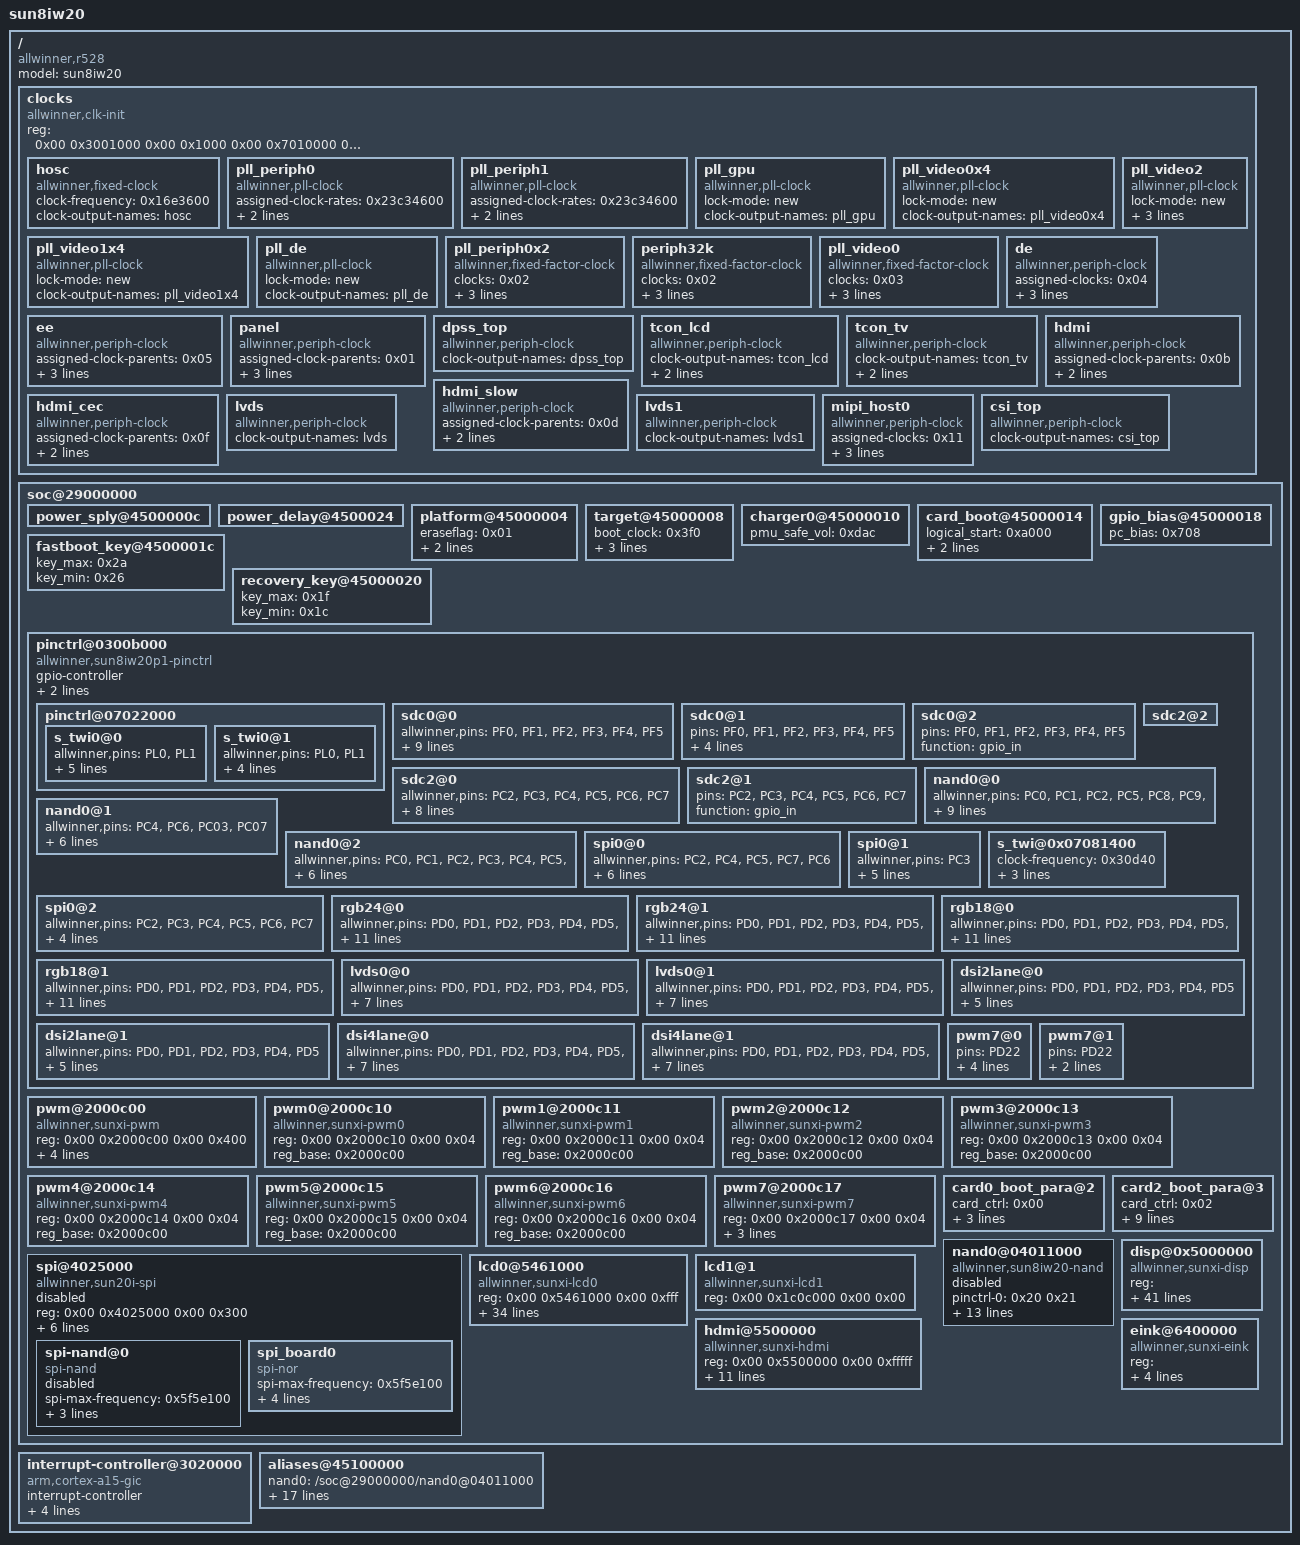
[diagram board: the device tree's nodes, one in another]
/dts-v1/;

/ {
	model = "sun8iw20";
	compatible = "allwinner,r528", "arm,sun8iw20p1";
	#address-cells = <0x02>;
	#size-cells = <0x02>;

	clocks {
		compatible = "allwinner,clk-init";
		device_type = "clocks";
		#address-cells = <0x02>;
		#size-cells = <0x02>;
		ranges;
		reg = <0x00 0x3001000 0x00 0x1000 0x00 0x7010000 0x00 0x400 0x00 0x7000000 0x00 0x04>;

		hosc {
			#clock-cells = <0x00>;
			compatible = "allwinner,fixed-clock";
			clock-frequency = <0x16e3600>;
			clock-output-names = "hosc";
			phandle = <0x0d>;
		};

		pll_periph0 {
			#clock-cells = <0x00>;
			compatible = "allwinner,pll-clock";
			assigned-clock-rates = <0x23c34600>;
			lock-mode = "new";
			clock-output-names = "pll_periph0";
			phandle = <0x02>;
		};

		pll_periph1 {
			#clock-cells = <0x00>;
			compatible = "allwinner,pll-clock";
			assigned-clock-rates = <0x23c34600>;
			lock-mode = "new";
			clock-output-names = "pll_periph1";
		};

		pll_gpu {
			#clock-cells = <0x00>;
			compatible = "allwinner,pll-clock";
			lock-mode = "new";
			clock-output-names = "pll_gpu";
		};

		pll_video0x4 {
			#clock-cells = <0x00>;
			compatible = "allwinner,pll-clock";
			lock-mode = "new";
			clock-output-names = "pll_video0x4";
			phandle = <0x03>;
		};

		pll_video1x4 {
			#clock-cells = <0x00>;
			compatible = "allwinner,pll-clock";
			lock-mode = "new";
			clock-output-names = "pll_video1x4";
			phandle = <0x0a>;
		};

		pll_video2 {
			#clock-cells = <0x00>;
			compatible = "allwinner,pll-clock";
			lock-mode = "new";
			assigned-clocks = <0x01>;
			assigned-clock-rates = <0x1406f400>;
			clock-output-names = "pll_video2";
			phandle = <0x01>;
		};

		pll_de {
			#clock-cells = <0x00>;
			compatible = "allwinner,pll-clock";
			lock-mode = "new";
			clock-output-names = "pll_de";
		};

		pll_periph0x2 {
			#clock-cells = <0x00>;
			compatible = "allwinner,fixed-factor-clock";
			clocks = <0x02>;
			clock-mult = <0x02>;
			clock-div = <0x01>;
			clock-output-names = "pll_periph0x2";
			phandle = <0x05>;
		};

		periph32k {
			#clock-cells = <0x00>;
			compatible = "allwinner,fixed-factor-clock";
			clocks = <0x02>;
			clock-mult = <0x02>;
			clock-div = <0x8f0d>;
			clock-output-names = "periph32k";
			phandle = <0x0f>;
		};

		pll_video0 {
			#clock-cells = <0x00>;
			compatible = "allwinner,fixed-factor-clock";
			clocks = <0x03>;
			clock-mult = <0x01>;
			clock-div = <0x04>;
			clock-output-names = "pll_video0";
			phandle = <0x0b>;
		};

		de {
			#clock-cells = <0x00>;
			compatible = "allwinner,periph-clock";
			assigned-clocks = <0x04>;
			assigned-clock-parents = <0x05>;
			assigned-clock-rates = <0x11e1a300>;
			clock-output-names = "de";
			phandle = <0x04>;
		};

		ee {
			#clock-cells = <0x00>;
			compatible = "allwinner,periph-clock";
			assigned-clock-parents = <0x05>;
			assigned-clock-rates = <0x11e1a300>;
			assigned-clocks = <0x06>;
			clock-output-names = "ee";
			phandle = <0x06>;
		};

		panel {
			#clock-cells = <0x00>;
			compatible = "allwinner,periph-clock";
			assigned-clock-parents = <0x01>;
			assigned-clock-rates = <0x1c9c380>;
			assigned-clocks = <0x07>;
			clock-output-names = "panel";
			phandle = <0x07>;
		};

		dpss_top {
			#clock-cells = <0x00>;
			compatible = "allwinner,periph-clock";
			clock-output-names = "dpss_top";
			phandle = <0x27>;
		};

		tcon_lcd {
			#clock-cells = <0x00>;
			compatible = "allwinner,periph-clock";
			clock-output-names = "tcon_lcd";
			assigned-clocks = <0x08>;
			assigned-clock-parents = <0x03>;
			phandle = <0x08>;
		};

		tcon_tv {
			#clock-cells = <0x00>;
			compatible = "allwinner,periph-clock";
			clock-output-names = "tcon_tv";
			assigned-clocks = <0x09>;
			assigned-clock-parents = <0x0a>;
			phandle = <0x09>;
		};

		hdmi {
			#clock-cells = <0x00>;
			compatible = "allwinner,periph-clock";
			assigned-clock-parents = <0x0b>;
			assigned-clocks = <0x0c>;
			clock-output-names = "hdmi";
			phandle = <0x0c>;
		};

		hdmi_slow {
			#clock-cells = <0x00>;
			compatible = "allwinner,periph-clock";
			assigned-clock-parents = <0x0d>;
			assigned-clocks = <0x0e>;
			clock-output-names = "hdmi_slow";
			phandle = <0x0e>;
		};

		hdmi_cec {
			#clock-cells = <0x00>;
			compatible = "allwinner,periph-clock";
			assigned-clock-parents = <0x0f>;
			assigned-clocks = <0x10>;
			clock-output-names = "hdmi_cec";
			phandle = <0x10>;
		};

		lvds {
			#clock-cells = <0x00>;
			compatible = "allwinner,periph-clock";
			clock-output-names = "lvds";
			phandle = <0x28>;
		};

		lvds1 {
			#clock-cells = <0x00>;
			compatible = "allwinner,periph-clock";
			clock-output-names = "lvds1";
		};

		mipi_host0 {
			#clock-cells = <0x00>;
			compatible = "allwinner,periph-clock";
			assigned-clocks = <0x11>;
			assigned-clock-parents = <0x02>;
			assigned-clock-rates = <0x8f0d180>;
			clock-output-names = "mipi_host0";
			phandle = <0x11>;
		};

		csi_top {
			#clock-cells = <0x00>;
			compatible = "allwinner,periph-clock";
			clock-output-names = "csi_top";
		};
	};

	soc@29000000 {
		#address-cells = <0x02>;
		#size-cells = <0x02>;

		power_sply@4500000c {
			device_type = "power_sply";
		};

		power_delay@4500024 {
			device_type = "power_delay";
		};

		platform@45000004 {
			device_type = "platform";
			eraseflag = <0x01>;
			next_work = <0x03>;
			debug_mode = <0x01>;
		};

		target@45000008 {
			device_type = "target";
			boot_clock = <0x3f0>;
			storage_type = <0xffffffff>;
			burn_key = <0x01>;
			dragonboard_test = <0x00>;
		};

		charger0@45000010 {
			device_type = "charger0";
			pmu_safe_vol = <0xdac>;
		};

		card_boot@45000014 {
			device_type = "card_boot";
			logical_start = <0xa000>;
			sprite_gpio0 = <0x12 0x07 0x06 0x01 0xffffffff 0xffffffff 0x01>;
		};

		gpio_bias@45000018 {
			device_type = "gpio_bias";
			pc_bias = <0x708>;
		};

		fastboot_key@4500001c {
			device_type = "fastboot_key";
			key_max = <0x2a>;
			key_min = <0x26>;
		};

		recovery_key@45000020 {
			device_type = "recovery_key";
			key_max = <0x1f>;
			key_min = <0x1c>;
		};

		pinctrl@0300b000 {
			compatible = "allwinner,sun8iw20p1-pinctrl";
			device_type = "pio";
			gpio-controller;
			#size-cells = <0x00>;
			#gpio-cells = <0x06>;
			input-debounce = <0x00 0x00 0x00 0x00 0x00 0x00 0x00 0x00 0x00>;
			phandle = <0x12>;

			pinctrl@07022000 {

				s_twi0@0 {
					allwinner,pins = "PL0", "PL1";
					allwinner,pname = "s_twi0_scl", "s_twi0_sda";
					allwinner,function = "s_twi0";
					allwinner,muxsel = <0x02>;
					allwinner,drive = <0x01>;
					allwinner,pull = <0x01>;
					phandle = <0x13>;
				};

				s_twi0@1 {
					allwinner,pins = "PL0", "PL1";
					allwinner,function = "io_disabled";
					allwinner,muxsel = <0x07>;
					allwinner,drive = <0x01>;
					allwinner,pull = <0x00>;
				};
			};

			sdc0@0 {
				allwinner,pins = "PF0", "PF1", "PF2", "PF3", "PF4", "PF5";
				allwinner,function = "sdc0";
				allwinner,muxsel = <0x02>;
				allwinner,drive = <0x03>;
				allwinner,pull = <0x01>;
				pins = "PF0", "PF1", "PF2", "PF3", "PF4", "PF5";
				function = "sdc0";
				drive-strength = <0x1e>;
				bias-pull-up;
				power-source = <0xce4>;
				phandle = <0x1e>;
			};

			sdc0@1 {
				pins = "PF0", "PF1", "PF2", "PF3", "PF4", "PF5";
				function = "sdc0";
				drive-strength = <0x1e>;
				bias-pull-up;
				power-source = <0x708>;
			};

			sdc0@2 {
				pins = "PF0", "PF1", "PF2", "PF3", "PF4", "PF5";
				function = "gpio_in";
			};

			sdc2@0 {
				allwinner,pins = "PC2", "PC3", "PC4", "PC5", "PC6", "PC7";
				allwinner,function = "sdc2";
				allwinner,muxsel = <0x03>;
				allwinner,drive = <0x03>;
				allwinner,pull = <0x01>;
				pins = "PC2", "PC3", "PC4", "PC5", "PC6", "PC7";
				function = "sdc2";
				drive-strength = <0x1e>;
				bias-pull-up;
				phandle = <0x1f>;
			};

			sdc2@1 {
				pins = "PC2", "PC3", "PC4", "PC5", "PC6", "PC7";
				function = "gpio_in";
			};

			sdc2@2 {
			};

			nand0@0 {
				allwinner,pins = "PC0", "PC1", "PC2", "PC5", "PC8", "PC9", "PC10", "PC11", "PC12", "PC13", "PC14", "PC15", "PC16";
				allwinner,pname = "nand0_we", "nand0_ale", "nand0_cle", "nand0_nre", "nand0_d0", "nand0_d1", "nand0_d2", "nand0_d3", "nand0_d4", "nand0_d5", "nand0_d6", "nand0_d7", "nand0_ndqs";
				allwinner,function = "nand0";
				allwinner,muxsel = <0x02>;
				allwinner,drive = <0x01>;
				allwinner,pull = <0x00>;
				phandle = <0x20>;
			};

			nand0@1 {
				allwinner,pins = "PC4", "PC6", "PC03", "PC07";
				allwinner,pname = "nand0_ce0", "nand0_rb0", "nand0_ce1", "nand0_rb1";
				allwinner,function = "nand0";
				allwinner,muxsel = <0x02>;
				allwinner,drive = <0x01>;
				allwinner,pull = <0x01>;
				phandle = <0x21>;
			};

			nand0@2 {
				allwinner,pins = "PC0", "PC1", "PC2", "PC3", "PC4", "PC5", "PC6", "PC7", "PC8", "PC9", "PC10", "PC11", "PC12", "PC13", "PC14", "PC15", "PC16";
				allwinner,function = "io_disabled";
				allwinner,muxsel = <0x07>;
				allwinner,drive = <0x01>;
				allwinner,pull = <0x00>;
				phandle = <0x22>;
			};

			spi0@0 {
				allwinner,pins = "PC2", "PC4", "PC5", "PC7", "PC6";
				allwinner,pname = "spi0_sclk", "spi0_mosi", "spi0_miso", "spi0_hold", "spi0_wp";
				allwinner,function = "spi0";
				allwinner,muxsel = <0x02>;
				allwinner,drive = <0x01>;
				allwinner,pull = <0x00>;
				phandle = <0x23>;
			};

			spi0@1 {
				allwinner,pins = "PC3";
				allwinner,pname = "spi0_cs0";
				allwinner,function = "spi0";
				allwinner,muxsel = <0x02>;
				allwinner,drive = <0x01>;
				allwinner,pull = <0x01>;
				phandle = <0x24>;
			};

			spi0@2 {
				allwinner,pins = "PC2", "PC3", "PC4", "PC5", "PC6", "PC7";
				allwinner,function = "gpio_in";
				allwinner,muxsel = <0x00>;
				allwinner,drive = <0x01>;
				allwinner,pull = <0x00>;
				phandle = <0x25>;
			};

			s_twi@0x07081400 {
				clock-frequency = <0x30d40>;
				pinctrl-0 = <0x13>;
				no_suspend = <0x01>;
				twi_drv_used = <0x01>;
				status = "okay";
			};

			rgb24@0 {
				allwinner,pins = "PD0", "PD1", "PD2", "PD3", "PD4", "PD5", "PD6", "PD7", "PD8", "PD9", "PD10", "PD11", "PD12", "PD13", "PD14", "PD15", "PD16", "PD17", "PD18", "PD19", "PD20", "PD21", "PB2", "PB3", "PB4", "PB5", "PB6", "PB7";
				allwinner,pname = "PD0", "PD1", "PD2", "PD3", "PD4", "PD5", "PD6", "PD7", "PD8", "PD9", "PD10", "PD11", "PD12", "PD13", "PD14", "PD15", "PD16", "PD17", "PD18", "PD19", "PD20", "PD21", "PB2", "PB3", "PB4", "PB5", "PB6", "PB7";
				allwinner,function = "rgb18";
				allwinner,muxsel = <0x02>;
				allwinner,drive = <0x03>;
				allwinner,pull = <0x00>;
			};

			rgb24@1 {
				allwinner,pins = "PD0", "PD1", "PD2", "PD3", "PD4", "PD5", "PD6", "PD7", "PD8", "PD9", "PD10", "PD11", "PD12", "PD13", "PD14", "PD15", "PD16", "PD17", "PD18", "PD19", "PD20", "PD21", "PB2", "PB3", "PB4", "PB5", "PB6", "PB7";
				allwinner,pname = "PD0", "PD1", "PD2", "PD3", "PD4", "PD5", "PD6", "PD7", "PD8", "PD9", "PD10", "PD11", "PD12", "PD13", "PD14", "PD15", "PD16", "PD17", "PD18", "PD19", "PD20", "PD21", "PB2", "PB3", "PB4", "PB5", "PB6", "PB7";
				allwinner,function = "rgb18_suspend";
				allwinner,muxsel = <0x0f>;
				allwinner,drive = <0x01>;
				allwinner,pull = <0x00>;
			};

			rgb18@0 {
				allwinner,pins = "PD0", "PD1", "PD2", "PD3", "PD4", "PD5", "PD6", "PD7", "PD8", "PD9", "PD10", "PD11", "PD12", "PD13", "PD14", "PD15", "PD16", "PD17", "PD18", "PD19", "PD20", "PD21";
				allwinner,pname = "PD0", "PD1", "PD2", "PD3", "PD4", "PD5", "PD6", "PD7", "PD8", "PD9", "PD10", "PD11", "PD12", "PD13", "PD14", "PD15", "PD16", "PD17", "PD18", "PD19", "PD20", "PD21";
				allwinner,function = "rgb18";
				allwinner,muxsel = <0x02>;
				allwinner,drive = <0x03>;
				allwinner,pull = <0x00>;
			};

			rgb18@1 {
				allwinner,pins = "PD0", "PD1", "PD2", "PD3", "PD4", "PD5", "PD6", "PD7", "PD8", "PD9", "PD10", "PD11", "PD12", "PD13", "PD14", "PD15", "PD16", "PD17", "PD18", "PD19", "PD20", "PD21";
				allwinner,pname = "PD0", "PD1", "PD2", "PD3", "PD4", "PD5", "PD6", "PD7", "PD8", "PD9", "PD10", "PD11", "PD12", "PD13", "PD14", "PD15", "PD16", "PD17", "PD18", "PD19", "PD20", "PD21";
				allwinner,function = "rgb18_suspend";
				allwinner,muxsel = <0x07>;
				allwinner,drive = <0x01>;
				allwinner,pull = <0x00>;
			};

			lvds0@0 {
				allwinner,pins = "PD0", "PD1", "PD2", "PD3", "PD4", "PD5", "PD6", "PD7", "PD8", "PD9";
				allwinner,pname = "PD0", "PD1", "PD2", "PD3", "PD4", "PD5", "PD6", "PD7", "PD8", "PD9";
				allwinner,function = "lvds0";
				allwinner,muxsel = <0x03>;
				allwinner,drive = <0x03>;
				allwinner,pull = <0x00>;
				phandle = <0x29>;
			};

			lvds0@1 {
				allwinner,pins = "PD0", "PD1", "PD2", "PD3", "PD4", "PD5", "PD6", "PD7", "PD8", "PD9";
				allwinner,pname = "PD0", "PD1", "PD2", "PD3", "PD4", "PD5", "PD6", "PD7", "PD8", "PD9";
				allwinner,function = "io_disabled";
				allwinner,muxsel = <0x07>;
				allwinner,drive = <0x03>;
				allwinner,pull = <0x00>;
				phandle = <0x2a>;
			};

			dsi2lane@0 {
				allwinner,pins = "PD0", "PD1", "PD2", "PD3", "PD4", "PD5";
				allwinner,pname = "PD0", "PD1", "PD2", "PD3", "PD4", "PD5";
				allwinner,function = "dsi2lane";
				allwinner,muxsel = <0x04>;
				allwinner,drive = <0x03>;
				allwinner,pull = <0x00>;
			};

			dsi2lane@1 {
				allwinner,pins = "PD0", "PD1", "PD2", "PD3", "PD4", "PD5";
				allwinner,pname = "PD0", "PD1", "PD2", "PD3", "PD4", "PD5";
				allwinner,function = "dsi2lane_suspend";
				allwinner,muxsel = <0x0f>;
				allwinner,drive = <0x01>;
				allwinner,pull = <0x00>;
			};

			dsi4lane@0 {
				allwinner,pins = "PD0", "PD1", "PD2", "PD3", "PD4", "PD5", "PD6", "PD7", "PD8", "PD9";
				allwinner,pname = "PD0", "PD1", "PD2", "PD3", "PD4", "PD5", "PD6", "PD7", "PD8", "PD9";
				allwinner,function = "dsi4lane";
				allwinner,muxsel = <0x04>;
				allwinner,drive = <0x03>;
				allwinner,pull = <0x00>;
			};

			dsi4lane@1 {
				allwinner,pins = "PD0", "PD1", "PD2", "PD3", "PD4", "PD5", "PD6", "PD7", "PD8", "PD9";
				allwinner,pname = "PD0", "PD1", "PD2", "PD3", "PD4", "PD5", "PD6", "PD7", "PD8", "PD9";
				allwinner,function = "dsi4lane_suspend";
				allwinner,muxsel = <0x07>;
				allwinner,drive = <0x01>;
				allwinner,pull = <0x00>;
			};

			pwm7@0 {
				pins = "PD22";
				function = "pwm7";
				muxsel = <0x05>;
				drive-strength = <0x0a>;
				bias-pull-up;
				phandle = <0x1c>;
			};

			pwm7@1 {
				pins = "PD22";
				muxsel = <0x00>;
				function = "gpio_in";
				phandle = <0x1d>;
			};
		};

		pwm@2000c00 {
			#pwm-cells = <0x03>;
			compatible = "allwinner,sunxi-pwm";
			reg = <0x00 0x2000c00 0x00 0x400>;
			pwm-number = <0x08>;
			pwm-base = <0x00>;
			sunxi-pwms = <0x14 0x15 0x16 0x17 0x18 0x19 0x1a 0x1b>;
		};

		pwm0@2000c10 {
			compatible = "allwinner,sunxi-pwm0";
			pinctrl-names = "active", "sleep";
			reg = <0x00 0x2000c10 0x00 0x04>;
			reg_base = <0x2000c00>;
			phandle = <0x14>;
		};

		pwm1@2000c11 {
			compatible = "allwinner,sunxi-pwm1";
			pinctrl-names = "active", "sleep";
			reg = <0x00 0x2000c11 0x00 0x04>;
			reg_base = <0x2000c00>;
			phandle = <0x15>;
		};

		pwm2@2000c12 {
			compatible = "allwinner,sunxi-pwm2";
			pinctrl-names = "active", "sleep";
			reg = <0x00 0x2000c12 0x00 0x04>;
			reg_base = <0x2000c00>;
			phandle = <0x16>;
		};

		pwm3@2000c13 {
			compatible = "allwinner,sunxi-pwm3";
			pinctrl-names = "active", "sleep";
			reg = <0x00 0x2000c13 0x00 0x04>;
			reg_base = <0x2000c00>;
			phandle = <0x17>;
		};

		pwm4@2000c14 {
			compatible = "allwinner,sunxi-pwm4";
			pinctrl-names = "active", "sleep";
			reg = <0x00 0x2000c14 0x00 0x04>;
			reg_base = <0x2000c00>;
			phandle = <0x18>;
		};

		pwm5@2000c15 {
			compatible = "allwinner,sunxi-pwm5";
			pinctrl-names = "active", "sleep";
			reg = <0x00 0x2000c15 0x00 0x04>;
			reg_base = <0x2000c00>;
			phandle = <0x19>;
		};

		pwm6@2000c16 {
			compatible = "allwinner,sunxi-pwm6";
			pinctrl-names = "active", "sleep";
			reg = <0x00 0x2000c16 0x00 0x04>;
			reg_base = <0x2000c00>;
			phandle = <0x1a>;
		};

		pwm7@2000c17 {
			compatible = "allwinner,sunxi-pwm7";
			pinctrl-names = "active", "sleep";
			reg = <0x00 0x2000c17 0x00 0x04>;
			reg_base = <0x2000c00>;
			pinctrl-0 = <0x1c>;
			pinctrl-1 = <0x1d>;
			status = "okay";
			phandle = <0x1b>;
		};

		card0_boot_para@2 {
			device_type = "card0_boot_para";
			card_ctrl = <0x00>;
			card_high_speed = <0x01>;
			card_line = <0x04>;
			pinctrl-0 = <0x1e>;
		};

		card2_boot_para@3 {
			device_type = "card2_boot_para";
			card_ctrl = <0x02>;
			card_high_speed = <0x01>;
			card_line = <0x04>;
			pinctrl-0 = <0x1f>;
			sdc_ex_dly_used = <0x02>;
			sdc_io_1v8 = <0x01>;
			sdc_tm4_win_th = <0x08>;
			sdc_tm4_hs200_max_freq = <0x96>;
			sdc_tm4_hs400_max_freq = <0x64>;
			sdc_type = "tm4";
		};

		nand0@04011000 {
			device_type = "nand0";
			compatible = "allwinner,sun8iw20-nand";
			pinctrl-names = "default", "sleep";
			pinctrl-0 = <0x20 0x21>;
			pinctrl-1 = <0x22>;
			nand0_regulator1 = "vcc-nand";
			nand0_regulator2 = "none";
			nand0_cache_level = <0x55aaaa55>;
			nand0_flush_cache_num = <0x55aaaa55>;
			nand0_capacity_level = <0x55aaaa55>;
			nand0_id_number_ctl = <0x55aaaa55>;
			nand0_print_level = <0x55aaaa55>;
			nand0_p0 = <0x55aaaa55>;
			nand0_p1 = <0x55aaaa55>;
			nand0_p2 = <0x55aaaa55>;
			nand0_p3 = <0x55aaaa55>;
			chip_code = "sun8iw20";
			status = "disabled";
		};

		spi@4025000 {
			#address-cells = <0x01>;
			#size-cells = <0x00>;
			compatible = "allwinner,sun20i-spi";
			device_type = "spi0";
			reg = <0x00 0x4025000 0x00 0x300>;
			clock-frequency = <0x5f5e100>;
			pinctrl-0 = <0x23 0x24>;
			pinctrl-1 = <0x25>;
			pinctrl-names = "default", "sleep";
			spi_slave_mode = <0x00>;
			spi0_cs_number = <0x01>;
			spi0_cs_bitmap = <0x01>;
			status = "disabled";

			spi-nand@0 {
				compatible = "spi-nand";
				spi-max-frequency = <0x5f5e100>;
				reg = <0x00>;
				spi-rx-bus-width = <0x01>;
				spi-tx-bus-width = <0x01>;
				status = "disabled";
			};

			spi_board0 {
				device_type = "spi_board0";
				compatible = "spi-nor";
				spi-max-frequency = <0x5f5e100>;
				m25p,fast-read = <0x01>;
				reg = <0x00>;
				spi-rx-bus-width = <0x04>;
				spi-tx-bus-width = <0x04>;
				status = "okay";
			};
		};

		disp@0x5000000 {
			compatible = "allwinner,sunxi-disp";
			reg = <0x00 0x5000000 0x00 0x3fffff 0x00 0x5460000 0x00 0xfff 0x00 0x5461000 0x00 0xfff 0x00 0x5470000 0x00 0xfff 0x00 0x5450000 0x00 0x1fff>;
			interrupts = <0x00 0x5a 0x04 0x00 0x5b 0x04 0x00 0x5c 0x04>;
			interrupt-parent = <0x26>;
			clocks = <0x04 0x27 0x08 0x09 0x28 0x11>;
			boot_disp = <0x00>;
			boot_disp1 = <0x00>;
			boot_disp2 = <0x00>;
			fb_base = <0x00>;
			status = "okay";
			disp_init_enable = <0x01>;
			disp_mode = <0x00>;
			screen0_output_type = <0x01>;
			screen0_output_mode = <0x04>;
			screen1_output_type = <0x01>;
			screen1_output_mode = <0x04>;
			screen1_output_format = <0x00>;
			screen1_output_bits = <0x00>;
			screen1_output_eotf = <0x04>;
			screen1_output_cs = <0x101>;
			screen1_output_dvi_hdmi = <0x02>;
			screen1_output_range = <0x02>;
			screen1_output_scan = <0x00>;
			screen1_output_aspect_ratio = <0x08>;
			dev0_output_type = <0x01>;
			dev0_output_mode = <0x04>;
			dev0_screen_id = <0x00>;
			dev0_do_hpd = <0x00>;
			dev1_output_type = <0x04>;
			dev1_output_mode = <0x0a>;
			dev1_screen_id = <0x01>;
			dev1_do_hpd = <0x01>;
			def_output_dev = <0x00>;
			hdmi_mode_check = <0x01>;
			fb0_format = <0x00>;
			fb0_width = <0x320>;
			fb0_height = <0x1e0>;
			fb1_format = <0x00>;
			fb1_width = <0x00>;
			fb1_height = <0x00>;
			chn_cfg_mode = <0x01>;
			disp_para_zone = <0x01>;
		};

		lcd0@5461000 {
			#address-cells = <0x02>;
			#size-cells = <0x02>;
			compatible = "allwinner,sunxi-lcd0";
			reg = <0x00 0x5461000 0x00 0xfff>;
			pinctrl-names = "active", "sleep";
			status = "okay";
			lcd_used = <0x01>;
			lcd_driver_name = "default_lcd";
			lcd_backlight = <0x32>;
			lcd_if = <0x03>;
			lcd_x = <0x320>;
			lcd_y = <0x1e0>;
			lcd_width = <0x6c>;
			lcd_height = <0x40>;
			lcd_dclk_freq = <0x21>;
			lcd_pwm_used = <0x01>;
			lcd_pwm_ch = <0x07>;
			lcd_pwm_freq = <0xc350>;
			lcd_pwm_pol = <0x01>;
			lcd_pwm_max_limit = <0xff>;
			lcd_hbp = <0x58>;
			lcd_ht = <0x3a0>;
			lcd_hspw = <0x30>;
			lcd_vbp = <0x23>;
			lcd_vt = <0x20d>;
			lcd_vspw = <0x03>;
			lcd_lvds_if = <0x00>;
			lcd_lvds_colordepth = <0x00>;
			lcd_lvds_mode = <0x00>;
			lcd_frm = <0x01>;
			lcd_hv_clk_phase = <0x00>;
			lcd_hv_sync_polarity = <0x00>;
			lcd_gamma_en = <0x00>;
			lcd_bright_curve_en = <0x00>;
			lcd_cmap_en = <0x00>;
			deu_mode = <0x00>;
			lcdgamma4iep = <0x16>;
			smart_color = <0x5a>;
			pinctrl-0 = <0x29>;
			pinctrl-1 = <0x2a>;
		};

		lcd1@1 {
			compatible = "allwinner,sunxi-lcd1";
			reg = <0x00 0x1c0c000 0x00 0x00>;
			pinctrl-names = "active", "sleep";
			status = "okay";
		};

		hdmi@5500000 {
			compatible = "allwinner,sunxi-hdmi";
			reg = <0x00 0x5500000 0x00 0xfffff>;
			interrupts = <0x00 0x5d 0x04>;
			interrupt-parent = <0x26>;
			clocks = <0x0e 0x10 0x09>;
			status = "okay";
			hdmi_used = <0x01>;
			hdmi_power_cnt = <0x00>;
			hdmi_hdcp_enable = <0x01>;
			hdmi_hdcp22_enable = <0x00>;
			hdmi_cec_support = <0x01>;
			hdmi_cec_super_standby = <0x00>;
			ddc_en_io_ctrl = <0x00>;
			power_io_ctrl = <0x00>;
		};

		eink@6400000 {
			compatible = "allwinner,sunxi-eink";
			pinctrl-names = "active", "sleep";
			reg = <0x00 0x6400000 0x00 0x1ffff 0x00 0x6000000 0x00 0x3fffff>;
			interrupts = <0x00 0x5a 0x04 0x00 0x58 0x04>;
			clocks = <0x04 0x06 0x07>;
			interrupt-parent = <0x26>;
			status = "okay";
		};
	};

	interrupt-controller@3020000 {
		compatible = "arm,cortex-a15-gic", "arm,cortex-a9-gic";
		#interrupt-cells = <0x03>;
		#address-cells = <0x00>;
		device_type = "gic";
		interrupt-controller;
		reg = <0x00 0x3021000 0x00 0x1000 0x00 0x3022000 0x00 0x2000 0x00 0x3024000 0x00 0x2000 0x00 0x3026000 0x00 0x2000>;
		interrupts = <0x01 0x09 0xf04>;
		interrupt-parent = <0x26>;
		phandle = <0x26>;
	};

	aliases@45100000 {
		nand0 = "/soc@29000000/nand0@04011000";
		twi6 = "/soc@29000000/pinctrl@0300b000/s_twi@0x07081400";
		pwm = "/soc@29000000/pwm@2000c00";
		pwm0 = "/soc@29000000/pwm0@2000c10";
		pwm1 = "/soc@29000000/pwm1@2000c11";
		pwm2 = "/soc@29000000/pwm2@2000c12";
		pwm3 = "/soc@29000000/pwm3@2000c13";
		pwm4 = "/soc@29000000/pwm4@2000c14";
		pwm5 = "/soc@29000000/pwm5@2000c15";
		pwm6 = "/soc@29000000/pwm6@2000c16";
		pwm7 = "/soc@29000000/pwm7@2000c17";
		disp = "/soc@29000000/disp@0x5000000";
		hdmi = "/soc@29000000/hdmi@5500000";
		lcd0 = "/soc@29000000/lcd0@5461000";
		lcd1 = "/soc@29000000/lcd1@1";
		eink = "/soc@29000000/eink@6400000";
		spi0 = "/soc@29000000/spi@4025000";
	};
};
